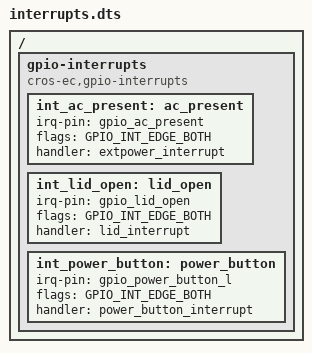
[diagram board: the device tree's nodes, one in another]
/* Copyright 2022 The Chromium OS Authors. All rights reserved.
 * Use of this source code is governed by a BSD-style license that can be
 * found in the LICENSE file.
 */

/ {
	gpio-interrupts {
		compatible = "cros-ec,gpio-interrupts";

		int_ac_present: ac_present {
			irq-pin = <&gpio_ac_present>;
			flags = <GPIO_INT_EDGE_BOTH>;
			handler = "extpower_interrupt";
		};
		int_lid_open: lid_open {
			irq-pin = <&gpio_lid_open>;
			flags = <GPIO_INT_EDGE_BOTH>;
			handler = "lid_interrupt";
		};
		int_power_button: power_button {
			irq-pin = <&gpio_power_button_l>;
			flags = <GPIO_INT_EDGE_BOTH>;
			handler = "power_button_interrupt";
		};
	};
};
